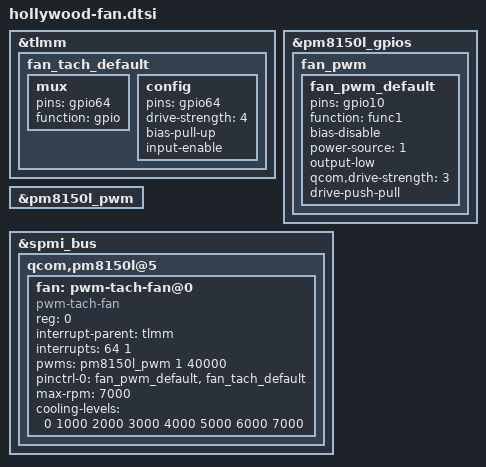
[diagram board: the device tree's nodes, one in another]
&tlmm {
	fan_tach_default: fan_tach_default {
		mux {
			pins = "gpio64";
			function = "gpio";
		};
		config {
			pins = "gpio64";
			drive-strength = <4>;
			bias-pull-up;
			input-enable;
		};
	};
};

&pm8150l_gpios {
	fan_pwm {
		fan_pwm_default: fan_pwm_default {
			pins = "gpio10";
			function = "func1";
			bias-disable;
			power-source = <1>;
			output-low;
			qcom,drive-strength = <3>;
			drive-push-pull;
			status = "okay";
		};
	};
};

&pm8150l_pwm {
	status = "okay";
};

&spmi_bus {
	qcom,pm8150l@5 {
		fan: pwm-tach-fan@0 {
			reg = <0>;
			compatible = "pwm-tach-fan";
			interrupt-parent = <&tlmm>;
			interrupts = <64 1>;
			interrupt-names = "fan_irq";
			/*25KHz -> 40000ns*/
			pwms = <&pm8150l_pwm 1 40000>;
			pinctrl-names = "default";
			pinctrl-0 = <&fan_pwm_default &fan_tach_default>;
			status = "okay";
			max-rpm = <7000>;
			#cooling-cells = <2>;
			cooling-levels = <0 1000 2000 3000 4000 5000 6000 7000>;
		};
	};
};
